# RESOLVER_RESOLVER_REGS_502CB000h register map
Vendor: Texas Instruments
Peripheral module from a debugger description file (folder AM263P).
Registers are 32-bit, read-write, reset 0x0 unless marked. A register's access mark holds for its fields unless they carry their own. Offsets are as the file gives them; lines under a group give offsets from that group; [hi:lo] are bit positions; {n}, {i} and the like mark numbered series; 'fields as' and 'values as' point back to an identical list; <NAME> marks a mode.

## RESOLVER_REGS (part 1 of 2)
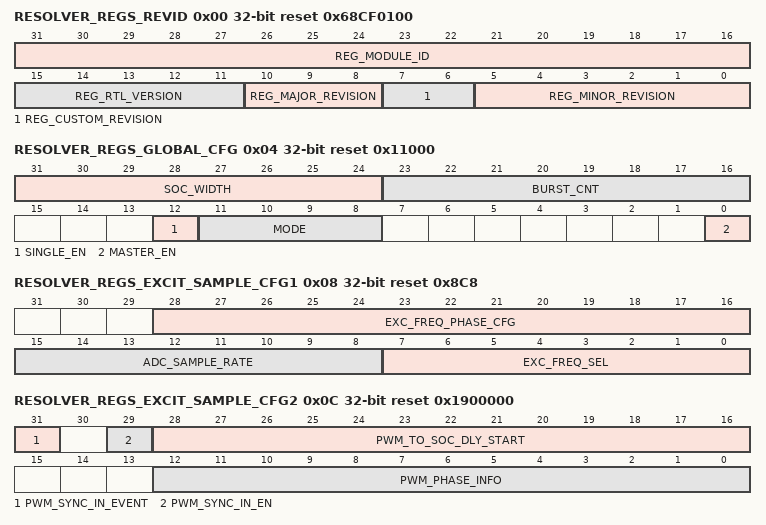
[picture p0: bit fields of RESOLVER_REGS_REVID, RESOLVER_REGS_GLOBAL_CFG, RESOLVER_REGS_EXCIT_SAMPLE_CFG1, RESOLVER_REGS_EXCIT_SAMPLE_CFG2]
0x00 RESOLVER_REGS_REVID ro reset 0x68CF0100 — The Module and Version Register identifies the module identifier and revision of the RTL module.
  [31:16] REG_MODULE_ID — Resolver module ID
  [15:11] REG_RTL_VERSION — RTL Version.
  [10:8] REG_MAJOR_REVISION — Major Revision.
  [7:6] REG_CUSTOM_REVISION — Custom Revision.
  [5:0] REG_MINOR_REVISION — Minor Revision.
0x04 RESOLVER_REGS_GLOBAL_CFG reset 0x11000 — Global Configuration.
  [31:24] SOC_WIDTH — Extension of Start Of Conversion(SOC) pulse width. Width = 40ns + 20ns*soc_width
  [23:16] BURST_CNT — This defines the number of burst per sample, 1 is no burst, 2 is 2 samples which will get avg ect.., only valid values are 1,2,4,8,16, and 32
  [12] SINGLE_EN — 1 single adc mode 0 diff adc mode
  [11:8] MODE — This defines the mode of the resolver , the user has 6 options to configure
  [0] MASTER_EN — Master Enable must leave disabled when cfg is updated0:Disabled1:Enabled When 0 it reset all counters, SM, SEQ, ect..
0x08 RESOLVER_REGS_EXCIT_SAMPLE_CFG1 reset 0x8C8 — Excitation and Sample Configuration1.
  [28:16] EXC_FREQ_PHASE_CFG — Defines when to start the8000counter to the SIN LUT, this is one time per master_en 0 -> 1
  [15:8] ADC_SAMPLE_RATE — ADC Over Sample Rate (<value> * 2) 0 = Reserved 1 = OSR2 .. 16 = OSR32 > 16 = Reserved
  [7:0] EXC_FREQ_SEL — Exciter Frequency select (<freq *10> * 10), only 200-20k, 100-10k, and 50-5k is valid
0x0C RESOLVER_REGS_EXCIT_SAMPLE_CFG2 access not given reset 0x1900000 — Excitation and Sample Configuration2.
  [31] PWM_SYNC_IN_EVENT — This tells SW we had a pwm_sync_in event after master_en is set, w1tc but new start you must de-assert mater_en to re-arm (access R/W1TC)
  [29] PWM_SYNC_IN_EN rw — 0 disable 1 enable the pwm_sync_in dep to start soc is
  [28:16] PWM_TO_SOC_DLY_START rw — This delay start of SEQ SOC in steps of 800KHz, this is a one time event per master_en 0 -> 1, first power up needs to be 500uS , so reset state of 400 will hit this
  [12:0] PWM_PHASE_INFO ro — This is the latched value of the last pwm_sync_in risge event
0x10 RESOLVER_REGS_EXCIT_SAMPLE_CFG3 reset 0xEF — Excitation and Sample Configuration2.
  [7:0] EXC_AMP_CTRL — Defines the amplitude scale, 249 is 100%, > 250 is res
0x14 RESOLVER_REGS_IRQSTATUS_RAW_SYS access not given — Interrupt Raw Status Register For Resolver.
  [0] SEQ_ERR — Raw status of error interrupt for seq_cmp_err Write 1 to set the (raw) status, mostly for debug. Writing a 0 has no effect. (access R/W1TS)
0x18 RESOLVER_REGS_IRQSTATUS_SYS access not given — Interrupt Status Register For Resolver.
  [0] SEQ_ERR — Enabled status of error interrupt for seq_cmp_err Write 1 to clear the status after interrupt has been serviced (raw status gets cleared, i.e. even if not enabled). Writing a 0 has no effect. (access R/W1TC)
0x1C RESOLVER_REGS_IRQENABLE_SET_SYS access not given — Interrupt Enable Set Register For Resolver.
  [0] SEQ_ERR — Enable set for seq_cmp_err . Writing a 1 will enable the interrupt, and set this bit as well as the corresponding Interrupt Enable Clear Register. Writing a 0 has no effect. (access R/W1TS)
0x20 RESOLVER_REGS_IRQENABLE_CLR_SYS access not given — Interrupt Enable Clear Register For Resolver.
  [0] SEQ_ERR — Enable clr for seq_cmp_err. Writing a 1 will disable the interrupt, and set this bit as well as the corresponding Interrupt Enable set Register. Writing a 0 has no effect. (access R/W1TS)
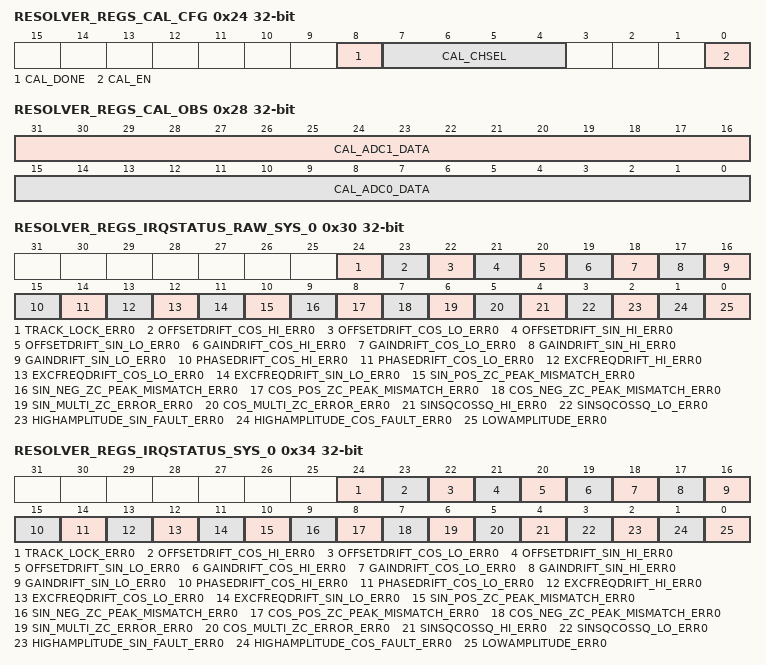
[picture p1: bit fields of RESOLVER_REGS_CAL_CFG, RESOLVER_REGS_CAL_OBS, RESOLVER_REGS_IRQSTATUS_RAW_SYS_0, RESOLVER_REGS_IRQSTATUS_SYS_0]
0x24 RESOLVER_REGS_CAL_CFG access not given — CAL Config.
  [8] CAL_DONE — This tells SW CAL data is updated, it will not do a new CAL sample until this is cleared (access R/W1TC)
  [7:4] CAL_CHSEL rw — This defines the ADC channel for ADC0 and ADC1 For 263P bit 4 is reserved To determine correct value per SOC refer to the ADC Spec for that SOC
  [0] CAL_EN rw — Enable CAL, each wrt of one will start cal, can not start new one until the other is done and done is cleared , to start a new cal just wrt a new one to this mmr
0x28 RESOLVER_REGS_CAL_OBS ro — CAL ADC0 and ADC1 Data.
  [31:16] CAL_ADC1_DATA — Signed ADC1 Data from CAL channel sample if mode enables ie not mode 1 and mode 2
  [15:0] CAL_ADC0_DATA — Signed ADC0 Data from CAL channel sample
0x30 RESOLVER_REGS_IRQSTATUS_RAW_SYS_0 access not given — Interrupt Raw Status Register for Core0.
  [24] TRACK_LOCK_ERR0 — Raw status of error interrupt for track_lock_err Write 1 to set the (raw) status, mostly for debug. Writing a 0 has no effect. (access R/W1TS)
  [23] OFFSETDRIFT_COS_HI_ERR0 — Raw status of error interrupt for offsetdrift_cos_hi_err Write 1 to set the (raw) status, mostly for debug. Writing a 0 has no effect. (access R/W1TS)
  [22] OFFSETDRIFT_COS_LO_ERR0 — Raw status of error interrupt for offsetdrift_cos_lo_err Write 1 to set the (raw) status, mostly for debug. Writing a 0 has no effect. (access R/W1TS)
  [21] OFFSETDRIFT_SIN_HI_ERR0 — Raw status of error interrupt for offsetdrift_sin_hi_err Write 1 to set the (raw) status, mostly for debug. Writing a 0 has no effect. (access R/W1TS)
  [20] OFFSETDRIFT_SIN_LO_ERR0 — Raw status of error interrupt for offsetdrift_sin_lo_err Write 1 to set the (raw) status, mostly for debug. Writing a 0 has no effect. (access R/W1TS)
  [19] GAINDRIFT_COS_HI_ERR0 — Raw status of error interrupt for gaindrift_cos_hi_err Write 1 to set the (raw) status, mostly for debug. Writing a 0 has no effect. (access R/W1TS)
  [18] GAINDRIFT_COS_LO_ERR0 — Raw status of error interrupt for gaindrift_cos_lo_err Write 1 to set the (raw) status, mostly for debug. Writing a 0 has no effect. (access R/W1TS)
  [17] GAINDRIFT_SIN_HI_ERR0 — Raw status of error interrupt for gaindrift_sin_hi_err Write 1 to set the (raw) status, mostly for debug. Writing a 0 has no effect. (access R/W1TS)
  [16] GAINDRIFT_SIN_LO_ERR0 — Raw status of error interrupt for gaindrift_sin_lo_err Write 1 to set the (raw) status, mostly for debug. Writing a 0 has no effect. (access R/W1TS)
  [15] PHASEDRIFT_COS_HI_ERR0 — Raw status of error interrupt for phasedrift_cos_hi_err Write 1 to set the (raw) status, mostly for debug. Writing a 0 has no effect. (access R/W1TS)
  [14] PHASEDRIFT_COS_LO_ERR0 — Raw status of error interrupt for phasedrift_cos_lo_err Write 1 to set the (raw) status, mostly for debug. Writing a 0 has no effect. (access R/W1TS)
  [13] EXCFREQDRIFT_HI_ERR0 — Raw status of error interrupt for excfreqdrift_hi_err Write 1 to set the (raw) status, mostly for debug. Writing a 0 has no effect. (access R/W1TS)
  [12] EXCFREQDRIFT_COS_LO_ERR0 — Raw status of error interrupt for excfreqdrift_cos_lo_err Write 1 to set the (raw) status, mostly for debug. Writing a 0 has no effect. (access R/W1TS)
  [11] EXCFREQDRIFT_SIN_LO_ERR0 — Raw status of error interrupt for excfreqdrift_sin_lo_err Write 1 to set the (raw) status, mostly for debug. Writing a 0 has no effect. (access R/W1TS)
  [10] SIN_POS_ZC_PEAK_MISMATCH_ERR0 — Raw status of error interrupt for sin_pos_zc_peak_mismatch_err Write 1 to set the (raw) status, mostly for debug. Writing a 0 has no effect. (access R/W1TS)
  [9] SIN_NEG_ZC_PEAK_MISMATCH_ERR0 — Raw status of error interrupt for sin_neg_zc_peak_mismatch_err Write 1 to set the (raw) status, mostly for debug. Writing a 0 has no effect. (access R/W1TS)
  [8] COS_POS_ZC_PEAK_MISMATCH_ERR0 — Raw status of error interrupt for cos_pos_zc_peak_mismatch_err Write 1 to set the (raw) status, mostly for debug. Writing a 0 has no effect. (access R/W1TS)
  [7] COS_NEG_ZC_PEAK_MISMATCH_ERR0 — Raw status of error interrupt for cos_neg_zc_peak_mismatch_err Write 1 to set the (raw) status, mostly for debug. Writing a 0 has no effect. (access R/W1TS)
  [6] SIN_MULTI_ZC_ERROR_ERR0 — Raw status of error interrupt for sin_multi_zc_error_err Write 1 to set the (raw) status, mostly for debug. Writing a 0 has no effect. (access R/W1TS)
  [5] COS_MULTI_ZC_ERROR_ERR0 — Raw status of error interrupt for cos_multi_zc_error_err Write 1 to set the (raw) status, mostly for debug. Writing a 0 has no effect. (access R/W1TS)
  [4] SINSQCOSSQ_HI_ERR0 — Raw status of error interrupt for sinsqcossq_hi_err Write 1 to set the (raw) status, mostly for debug. Writing a 0 has no effect. (access R/W1TS)
  [3] SINSQCOSSQ_LO_ERR0 — Raw status of error interrupt for sinsqcossq_lo_err Write 1 to set the (raw) status, mostly for debug. Writing a 0 has no effect. (access R/W1TS)
  [2] HIGHAMPLITUDE_SIN_FAULT_ERR0 — Raw status of error interrupt for highamplitude_sin_fault_err Write 1 to set the (raw) status, mostly for debug. Writing a 0 has no effect. (access R/W1TS)
  [1] HIGHAMPLITUDE_COS_FAULT_ERR0 — Raw status of error interrupt for highamplitude_cos_fault_err Write 1 to set the (raw) status, mostly for debug. Writing a 0 has no effect. (access R/W1TS)
  [0] LOWAMPLITUDE_ERR0 — Raw status of error interrupt for lowamplitude_err Write 1 to set the (raw) status, mostly for debug. Writing a 0 has no effect. (access R/W1TS)
0x34 RESOLVER_REGS_IRQSTATUS_SYS_0 access not given — Interrupt Status Register for Core0.
  [24] TRACK_LOCK_ERR0 — Enabled status of error interrupt for track_lock_err Write 1 to clear the status after interrupt has been serviced (raw status gets cleared, i.e. even if not enabled). Writing a 0 has no effect. (access R/W1TC)
  [23] OFFSETDRIFT_COS_HI_ERR0 — Enabled status of error interrupt for offsetdrift_cos_hi_err Write 1 to clear the status after interrupt has been serviced (raw status gets cleared, i.e. even if not enabled). Writing a 0 has no effect. (access R/W1TC)
  [22] OFFSETDRIFT_COS_LO_ERR0 — Enabled status of error interrupt for offsetdrift_cos_lo_err Write 1 to clear the status after interrupt has been serviced (raw status gets cleared, i.e. even if not enabled). Writing a 0 has no effect. (access R/W1TC)
  [21] OFFSETDRIFT_SIN_HI_ERR0 — Enabled status of error interrupt for offsetdrift_sin_hi_err Write 1 to clear the status after interrupt has been serviced (raw status gets cleared, i.e. even if not enabled). Writing a 0 has no effect. (access R/W1TC)
  [20] OFFSETDRIFT_SIN_LO_ERR0 — Enabled status of error interrupt for offsetdrift_sin_lo_err Write 1 to clear the status after interrupt has been serviced (raw status gets cleared, i.e. even if not enabled). Writing a 0 has no effect. (access R/W1TC)
  [19] GAINDRIFT_COS_HI_ERR0 — Enabled status of error interrupt for gaindrift_cos_hi_err Write 1 to clear the status after interrupt has been serviced (raw status gets cleared, i.e. even if not enabled). Writing a 0 has no effect. (access R/W1TC)
  [18] GAINDRIFT_COS_LO_ERR0 — Enabled status of error interrupt for gaindrift_cos_lo_err Write 1 to clear the status after interrupt has been serviced (raw status gets cleared, i.e. even if not enabled). Writing a 0 has no effect. (access R/W1TC)
  [17] GAINDRIFT_SIN_HI_ERR0 — Enabled status of error interrupt for gaindrift_sin_hi_err Write 1 to clear the status after interrupt has been serviced (raw status gets cleared, i.e. even if not enabled). Writing a 0 has no effect. (access R/W1TC)
  [16] GAINDRIFT_SIN_LO_ERR0 — Enabled status of error interrupt for gaindrift_sin_lo_err Write 1 to clear the status after interrupt has been serviced (raw status gets cleared, i.e. even if not enabled). Writing a 0 has no effect. (access R/W1TC)
  [15] PHASEDRIFT_COS_HI_ERR0 — Enabled status of error interrupt for phasedrift_cos_hi_err Write 1 to clear the status after interrupt has been serviced (raw status gets cleared, i.e. even if not enabled). Writing a 0 has no effect. (access R/W1TC)
  [14] PHASEDRIFT_COS_LO_ERR0 — Enabled status of error interrupt for phasedrift_cos_lo_err Write 1 to clear the status after interrupt has been serviced (raw status gets cleared, i.e. even if not enabled). Writing a 0 has no effect. (access R/W1TC)
  [13] EXCFREQDRIFT_HI_ERR0 — Enabled status of error interrupt for excfreqdrift_hi_err Write 1 to clear the status after interrupt has been serviced (raw status gets cleared, i.e. even if not enabled). Writing a 0 has no effect. (access R/W1TC)
  [12] EXCFREQDRIFT_COS_LO_ERR0 — Enabled status of error interrupt for excfreqdrift_cos_lo_err Write 1 to clear the status after interrupt has been serviced (raw status gets cleared, i.e. even if not enabled). Writing a 0 has no effect. (access R/W1TC)
  [11] EXCFREQDRIFT_SIN_LO_ERR0 — Enabled status of error interrupt for excfreqdrift_sin_lo_err Write 1 to clear the status after interrupt has been serviced (raw status gets cleared, i.e. even if not enabled). Writing a 0 has no effect. (access R/W1TC)
  [10] SIN_POS_ZC_PEAK_MISMATCH_ERR0 — Enabled status of error interrupt for sin_pos_zc_peak_mismatch_err Write 1 to clear the status after interrupt has been serviced (raw status gets cleared, i.e. even if not enabled). Writing a 0 has no effect. (access R/W1TC)
  [9] SIN_NEG_ZC_PEAK_MISMATCH_ERR0 — Enabled status of error interrupt for sin_neg_zc_peak_mismatch_err Write 1 to clear the status after interrupt has been serviced (raw status gets cleared, i.e. even if not enabled). Writing a 0 has no effect. (access R/W1TC)
  [8] COS_POS_ZC_PEAK_MISMATCH_ERR0 — Enabled status of error interrupt for cos_pos_zc_peak_mismatch_err Write 1 to clear the status after interrupt has been serviced (raw status gets cleared, i.e. even if not enabled). Writing a 0 has no effect. (access R/W1TC)
  [7] COS_NEG_ZC_PEAK_MISMATCH_ERR0 — Enabled status of error interrupt for cos_neg_zc_peak_mismatch_err Write 1 to clear the status after interrupt has been serviced (raw status gets cleared, i.e. even if not enabled). Writing a 0 has no effect. (access R/W1TC)
  [6] SIN_MULTI_ZC_ERROR_ERR0 — Enabled status of error interrupt for sin_multi_zc_error_err Write 1 to clear the status after interrupt has been serviced (raw status gets cleared, i.e. even if not enabled). Writing a 0 has no effect. (access R/W1TC)
  [5] COS_MULTI_ZC_ERROR_ERR0 — Enabled status of error interrupt for cos_multi_zc_error_err Write 1 to clear the status after interrupt has been serviced (raw status gets cleared, i.e. even if not enabled). Writing a 0 has no effect. (access R/W1TC)
  [4] SINSQCOSSQ_HI_ERR0 — Enabled status of error interrupt for sinsqcossq_hi_err Write 1 to clear the status after interrupt has been serviced (raw status gets cleared, i.e. even if not enabled). Writing a 0 has no effect. (access R/W1TC)
  [3] SINSQCOSSQ_LO_ERR0 — Enabled status of error interrupt for sinsqcossq_lo_err Write 1 to clear the status after interrupt has been serviced (raw status gets cleared, i.e. even if not enabled). Writing a 0 has no effect. (access R/W1TC)
  [2] HIGHAMPLITUDE_SIN_FAULT_ERR0 — Enabled status of error interrupt for highamplitude_sin_fault_err Write 1 to clear the status after interrupt has been serviced (raw status gets cleared, i.e. even if not enabled). Writing a 0 has no effect. (access R/W1TC)
  [1] HIGHAMPLITUDE_COS_FAULT_ERR0 — Enabled status of error interrupt for highamplitude_cos_fault_err Write 1 to clear the status after interrupt has been serviced (raw status gets cleared, i.e. even if not enabled). Writing a 0 has no effect. (access R/W1TC)
  [0] LOWAMPLITUDE_ERR0 — Enabled status of error interrupt for lowamplitude_err Write 1 to clear the status after interrupt has been serviced (raw status gets cleared, i.e. even if not enabled). Writing a 0 has no effect. (access R/W1TC)
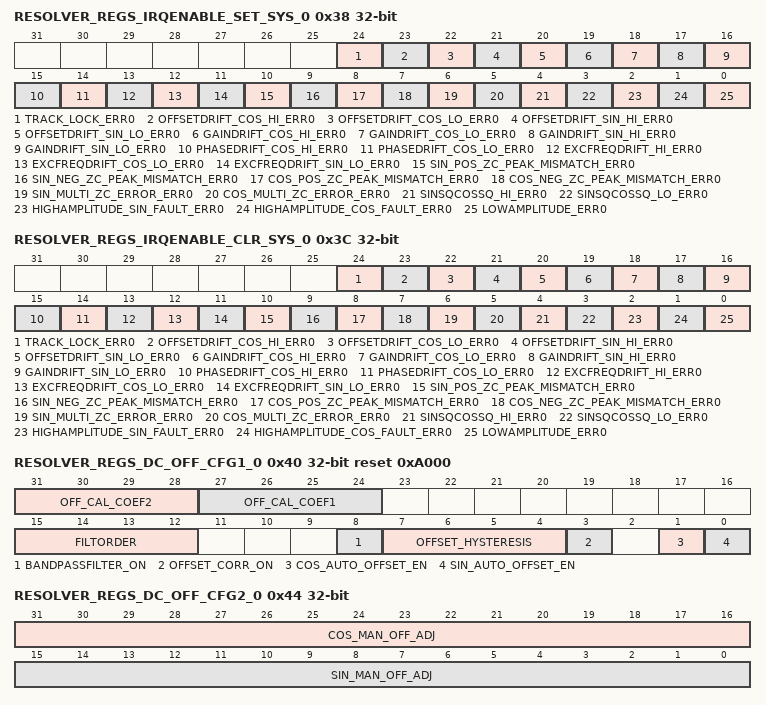
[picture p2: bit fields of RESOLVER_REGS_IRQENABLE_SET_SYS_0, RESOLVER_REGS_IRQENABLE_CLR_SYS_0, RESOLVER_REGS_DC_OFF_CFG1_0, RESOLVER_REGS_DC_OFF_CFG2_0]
0x38 RESOLVER_REGS_IRQENABLE_SET_SYS_0 access not given — Interrupt Enable Set Register for Core0.
  [24] TRACK_LOCK_ERR0 — Enable set for track_lock_err . Writing a 1 will enable the interrupt, and set this bit as well as the corresponding Interrupt Enable Clear Register. Writing a 0 has no effect. (access R/W1TS)
  [23] OFFSETDRIFT_COS_HI_ERR0 — Enable set for offsetdrift_cos_hi_err . Writing a 1 will enable the interrupt, and set this bit as well as the corresponding Interrupt Enable Clear Register. Writing a 0 has no effect. (access R/W1TS)
  [22] OFFSETDRIFT_COS_LO_ERR0 — Enable set for offsetdrift_cos_lo_err . Writing a 1 will enable the interrupt, and set this bit as well as the corresponding Interrupt Enable Clear Register. Writing a 0 has no effect. (access R/W1TS)
  [21] OFFSETDRIFT_SIN_HI_ERR0 — Enable set for offsetdrift_sin_hi_err . Writing a 1 will enable the interrupt, and set this bit as well as the corresponding Interrupt Enable Clear Register. Writing a 0 has no effect. (access R/W1TS)
  [20] OFFSETDRIFT_SIN_LO_ERR0 — Enable set for offsetdrift_sin_lo_err . Writing a 1 will enable the interrupt, and set this bit as well as the corresponding Interrupt Enable Clear Register. Writing a 0 has no effect. (access R/W1TS)
  [19] GAINDRIFT_COS_HI_ERR0 — Enable set for gaindrift_cos_hi_err . Writing a 1 will enable the interrupt, and set this bit as well as the corresponding Interrupt Enable Clear Register. Writing a 0 has no effect. (access R/W1TS)
  [18] GAINDRIFT_COS_LO_ERR0 — Enable set for gaindrift_cos_lo_err . Writing a 1 will enable the interrupt, and set this bit as well as the corresponding Interrupt Enable Clear Register. Writing a 0 has no effect. (access R/W1TS)
  [17] GAINDRIFT_SIN_HI_ERR0 — Enable set for gaindrift_sin_hi_err . Writing a 1 will enable the interrupt, and set this bit as well as the corresponding Interrupt Enable Clear Register. Writing a 0 has no effect. (access R/W1TS)
  [16] GAINDRIFT_SIN_LO_ERR0 — Enable set for gaindrift_sin_lo_err . Writing a 1 will enable the interrupt, and set this bit as well as the corresponding Interrupt Enable Clear Register. Writing a 0 has no effect. (access R/W1TS)
  [15] PHASEDRIFT_COS_HI_ERR0 — Enable set for phasedrift_cos_hi_err . Writing a 1 will enable the interrupt, and set this bit as well as the corresponding Interrupt Enable Clear Register. Writing a 0 has no effect. (access R/W1TS)
  [14] PHASEDRIFT_COS_LO_ERR0 — Enable set for phasedrift_cos_lo_err . Writing a 1 will enable the interrupt, and set this bit as well as the corresponding Interrupt Enable Clear Register. Writing a 0 has no effect. (access R/W1TS)
  [13] EXCFREQDRIFT_HI_ERR0 — Enable set for excfreqdrift_hi_err . Writing a 1 will enable the interrupt, and set this bit as well as the corresponding Interrupt Enable Clear Register. Writing a 0 has no effect. (access R/W1TS)
  [12] EXCFREQDRIFT_COS_LO_ERR0 — Enable set for excfreqdrift_cos_lo_err . Writing a 1 will enable the interrupt, and set this bit as well as the corresponding Interrupt Enable Clear Register. Writing a 0 has no effect. (access R/W1TS)
  [11] EXCFREQDRIFT_SIN_LO_ERR0 — Enable set for excfreqdrift_sin_lo_err . Writing a 1 will enable the interrupt, and set this bit as well as the corresponding Interrupt Enable Clear Register. Writing a 0 has no effect. (access R/W1TS)
  [10] SIN_POS_ZC_PEAK_MISMATCH_ERR0 — Enable set for sin_pos_zc_peak_mismatch_err . Writing a 1 will enable the interrupt, and set this bit as well as the corresponding Interrupt Enable Clear Register. Writing a 0 has no effect. (access R/W1TS)
  [9] SIN_NEG_ZC_PEAK_MISMATCH_ERR0 — Enable set for sin_neg_zc_peak_mismatch_err . Writing a 1 will enable the interrupt, and set this bit as well as the corresponding Interrupt Enable Clear Register. Writing a 0 has no effect. (access R/W1TS)
  [8] COS_POS_ZC_PEAK_MISMATCH_ERR0 — Enable set for cos_pos_zc_peak_mismatch_err . Writing a 1 will enable the interrupt, and set this bit as well as the corresponding Interrupt Enable Clear Register. Writing a 0 has no effect. (access R/W1TS)
  [7] COS_NEG_ZC_PEAK_MISMATCH_ERR0 — Enable set for cos_neg_zc_peak_mismatch_err . Writing a 1 will enable the interrupt, and set this bit as well as the corresponding Interrupt Enable Clear Register. Writing a 0 has no effect. (access R/W1TS)
  [6] SIN_MULTI_ZC_ERROR_ERR0 — Enable set for sin_multi_zc_error_err . Writing a 1 will enable the interrupt, and set this bit as well as the corresponding Interrupt Enable Clear Register. Writing a 0 has no effect. (access R/W1TS)
  [5] COS_MULTI_ZC_ERROR_ERR0 — Enable set for cos_multi_zc_error_err . Writing a 1 will enable the interrupt, and set this bit as well as the corresponding Interrupt Enable Clear Register. Writing a 0 has no effect. (access R/W1TS)
  [4] SINSQCOSSQ_HI_ERR0 — Enable set for sinsqcossq_hi_err . Writing a 1 will enable the interrupt, and set this bit as well as the corresponding Interrupt Enable Clear Register. Writing a 0 has no effect. (access R/W1TS)
  [3] SINSQCOSSQ_LO_ERR0 — Enable set for sinsqcossq_lo_err . Writing a 1 will enable the interrupt, and set this bit as well as the corresponding Interrupt Enable Clear Register. Writing a 0 has no effect. (access R/W1TS)
  [2] HIGHAMPLITUDE_SIN_FAULT_ERR0 — Enable set for highamplitude_sin_fault_err . Writing a 1 will enable the interrupt, and set this bit as well as the corresponding Interrupt Enable Clear Register. Writing a 0 has no effect. (access R/W1TS)
  [1] HIGHAMPLITUDE_COS_FAULT_ERR0 — Enable set for highamplitude_cos_fault_err . Writing a 1 will enable the interrupt, and set this bit as well as the corresponding Interrupt Enable Clear Register. Writing a 0 has no effect. (access R/W1TS)
  [0] LOWAMPLITUDE_ERR0 — Enable set for lowamplitude_err . Writing a 1 will enable the interrupt, and set this bit as well as the corresponding Interrupt Enable Clear Register. Writing a 0 has no effect. (access R/W1TS)
0x3C RESOLVER_REGS_IRQENABLE_CLR_SYS_0 access not given — Interrupt Enable Clear Register for Core0.
  [24] TRACK_LOCK_ERR0 — Enable clr for track_lock_err. Writing a 1 will disable the interrupt, and set this bit as well as the corresponding Interrupt Enable set Register. Writing a 0 has no effect. (access R/W1TS)
  [23] OFFSETDRIFT_COS_HI_ERR0 — Enable clr for offsetdrift_cos_hi_err. Writing a 1 will disable the interrupt, and set this bit as well as the corresponding Interrupt Enable set Register. Writing a 0 has no effect. (access R/W1TS)
  [22] OFFSETDRIFT_COS_LO_ERR0 — Enable clr for offsetdrift_cos_lo_err. Writing a 1 will disable the interrupt, and set this bit as well as the corresponding Interrupt Enable set Register. Writing a 0 has no effect. (access R/W1TS)
  [21] OFFSETDRIFT_SIN_HI_ERR0 — Enable clr for offsetdrift_sin_hi_err. Writing a 1 will disable the interrupt, and set this bit as well as the corresponding Interrupt Enable set Register. Writing a 0 has no effect. (access R/W1TS)
  [20] OFFSETDRIFT_SIN_LO_ERR0 — Enable clr for offsetdrift_sin_lo_err. Writing a 1 will disable the interrupt, and set this bit as well as the corresponding Interrupt Enable set Register. Writing a 0 has no effect. (access R/W1TS)
  [19] GAINDRIFT_COS_HI_ERR0 — Enable clr for gaindrift_cos_hi_err. Writing a 1 will disable the interrupt, and set this bit as well as the corresponding Interrupt Enable set Register. Writing a 0 has no effect. (access R/W1TS)
  [18] GAINDRIFT_COS_LO_ERR0 — Enable clr for gaindrift_cos_lo_err. Writing a 1 will disable the interrupt, and set this bit as well as the corresponding Interrupt Enable set Register. Writing a 0 has no effect. (access R/W1TS)
  [17] GAINDRIFT_SIN_HI_ERR0 — Enable clr for gaindrift_sin_hi_err. Writing a 1 will disable the interrupt, and set this bit as well as the corresponding Interrupt Enable set Register. Writing a 0 has no effect. (access R/W1TS)
  [16] GAINDRIFT_SIN_LO_ERR0 — Enable clr for gaindrift_sin_lo_err. Writing a 1 will disable the interrupt, and set this bit as well as the corresponding Interrupt Enable set Register. Writing a 0 has no effect. (access R/W1TS)
  [15] PHASEDRIFT_COS_HI_ERR0 — Enable clr for phasedrift_cos_hi_err. Writing a 1 will disable the interrupt, and set this bit as well as the corresponding Interrupt Enable set Register. Writing a 0 has no effect. (access R/W1TS)
  [14] PHASEDRIFT_COS_LO_ERR0 — Enable clr for phasedrift_cos_lo_err. Writing a 1 will disable the interrupt, and set this bit as well as the corresponding Interrupt Enable set Register. Writing a 0 has no effect. (access R/W1TS)
  [13] EXCFREQDRIFT_HI_ERR0 — Enable clr for excfreqdrift_hi_err. Writing a 1 will disable the interrupt, and set this bit as well as the corresponding Interrupt Enable set Register. Writing a 0 has no effect. (access R/W1TS)
  [12] EXCFREQDRIFT_COS_LO_ERR0 — Enable clr for excfreqdrift_cos_lo_err. Writing a 1 will disable the interrupt, and set this bit as well as the corresponding Interrupt Enable set Register. Writing a 0 has no effect. (access R/W1TS)
  [11] EXCFREQDRIFT_SIN_LO_ERR0 — Enable clr for excfreqdrift_sin_lo_err. Writing a 1 will disable the interrupt, and set this bit as well as the corresponding Interrupt Enable set Register. Writing a 0 has no effect. (access R/W1TS)
  [10] SIN_POS_ZC_PEAK_MISMATCH_ERR0 — Enable clr for sin_pos_zc_peak_mismatch_err. Writing a 1 will disable the interrupt, and set this bit as well as the corresponding Interrupt Enable set Register. Writing a 0 has no effect. (access R/W1TS)
  [9] SIN_NEG_ZC_PEAK_MISMATCH_ERR0 — Enable clr for sin_neg_zc_peak_mismatch_err. Writing a 1 will disable the interrupt, and set this bit as well as the corresponding Interrupt Enable set Register. Writing a 0 has no effect. (access R/W1TS)
  [8] COS_POS_ZC_PEAK_MISMATCH_ERR0 — Enable clr for cos_pos_zc_peak_mismatch_err. Writing a 1 will disable the interrupt, and set this bit as well as the corresponding Interrupt Enable set Register. Writing a 0 has no effect. (access R/W1TS)
  [7] COS_NEG_ZC_PEAK_MISMATCH_ERR0 — Enable clr for cos_neg_zc_peak_mismatch_err. Writing a 1 will disable the interrupt, and set this bit as well as the corresponding Interrupt Enable set Register. Writing a 0 has no effect. (access R/W1TS)
  [6] SIN_MULTI_ZC_ERROR_ERR0 — Enable clr for sin_multi_zc_error_err. Writing a 1 will disable the interrupt, and set this bit as well as the corresponding Interrupt Enable set Register. Writing a 0 has no effect. (access R/W1TS)
  [5] COS_MULTI_ZC_ERROR_ERR0 — Enable clr for cos_multi_zc_error_err. Writing a 1 will disable the interrupt, and set this bit as well as the corresponding Interrupt Enable set Register. Writing a 0 has no effect. (access R/W1TS)
  [4] SINSQCOSSQ_HI_ERR0 — Enable clr for sinsqcossq_hi_err. Writing a 1 will disable the interrupt, and set this bit as well as the corresponding Interrupt Enable set Register. Writing a 0 has no effect. (access R/W1TS)
  [3] SINSQCOSSQ_LO_ERR0 — Enable clr for sinsqcossq_lo_err. Writing a 1 will disable the interrupt, and set this bit as well as the corresponding Interrupt Enable set Register. Writing a 0 has no effect. (access R/W1TS)
  [2] HIGHAMPLITUDE_SIN_FAULT_ERR0 — Enable clr for highamplitude_sin_fault_err. Writing a 1 will disable the interrupt, and set this bit as well as the corresponding Interrupt Enable set Register. Writing a 0 has no effect. (access R/W1TS)
  [1] HIGHAMPLITUDE_COS_FAULT_ERR0 — Enable clr for highamplitude_cos_fault_err. Writing a 1 will disable the interrupt, and set this bit as well as the corresponding Interrupt Enable set Register. Writing a 0 has no effect. (access R/W1TS)
  [0] LOWAMPLITUDE_ERR0 — Enable clr for lowamplitude_err. Writing a 1 will disable the interrupt, and set this bit as well as the corresponding Interrupt Enable set Register. Writing a 0 has no effect. (access R/W1TS)
0x40 RESOLVER_REGS_DC_OFF_CFG1_0 reset 0xA000 — DC Offset Config1.
  [31:28] OFF_CAL_COEF2 — Offset calibration coefficient2 dc offset
  [27:24] OFF_CAL_COEF1 — Offset calibration coefficient1 dc offset
  [15:12] FILTORDER — NOT USED
  [8] BANDPASSFILTER_ON — To enable the bandpass filter before DC offset logix
  [7:4] OFFSET_HYSTERESIS — unsigned. Absolute hysteresis limit.4b(no decimal points) with the16bLSB, ADC data coming16bto the resolver
  [3] OFFSET_CORR_ON — DC Offset Correction On
  [1] COS_AUTO_OFFSET_EN — NOT_USED
  [0] SIN_AUTO_OFFSET_EN — NOT USED
0x44 RESOLVER_REGS_DC_OFF_CFG2_0 — DC Offset Config2.
  [31:16] COS_MAN_OFF_ADJ — Signed Cos manual dc offset
  [15:0] SIN_MAN_OFF_ADJ — Signed Sin manual dc offset
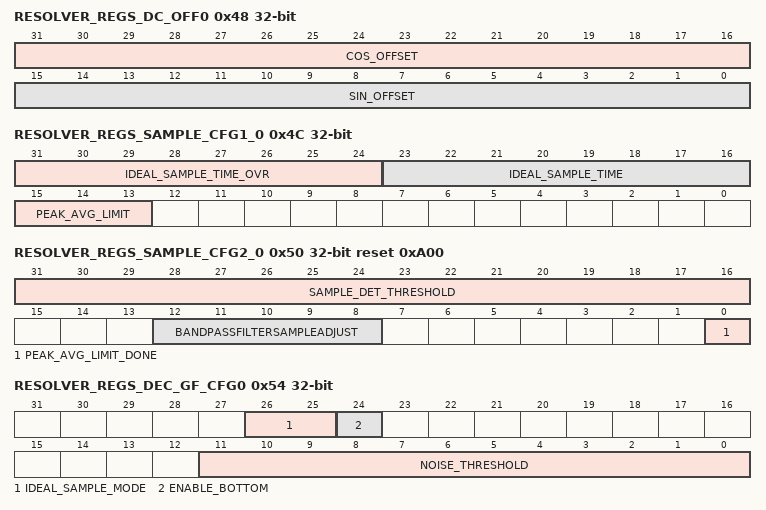
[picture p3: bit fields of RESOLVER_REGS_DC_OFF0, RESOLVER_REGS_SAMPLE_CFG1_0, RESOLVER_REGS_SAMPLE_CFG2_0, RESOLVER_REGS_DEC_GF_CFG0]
0x48 RESOLVER_REGS_DC_OFF0 ro — DC Offset.
  [31:16] COS_OFFSET — Signed Cos auto dc offset
  [15:0] SIN_OFFSET — Signed Sin auto dc offset
0x4C RESOLVER_REGS_SAMPLE_CFG1_0 access per field — Ideal Sample Config1.
  [31:24] IDEAL_SAMPLE_TIME_OVR rw — Ideal sample count Override
  [23:16] IDEAL_SAMPLE_TIME ro — Current Ideal sample count, round down
  [15:13] PEAK_AVG_LIMIT rw — 2^n peakaveragelimit is how many times to average the ideal peak point: 0 to 7
0x50 RESOLVER_REGS_SAMPLE_CFG2_0 access not given reset 0xA00 — Ideal Sample Config2.
  [31:16] SAMPLE_DET_THRESHOLD rw — Abs value, the sig needs to be above to trigger the peak detect
  [12:8] BANDPASSFILTERSAMPLEADJUST rw — Offset compensate the ideal phase time selection if bpass filter enabled note when you are in manual mode, this value is not longer added
  [0] PEAK_AVG_LIMIT_DONE — Ideal sample count training completed, Wrt 1 to Clr (access R/W1TC)
0x54 RESOLVER_REGS_DEC_GF_CFG0 — Dec GF Config.
  [26:25] IDEAL_SAMPLE_MODE — Ideal sample time detection: 0 autodetect, 1 detect on sin channel 2 on cos channel 3 manual
  [24] ENABLE_BOTTOM — This enables bottom wave to get used in the avg
  [11:0] NOISE_THRESHOLD — Abs value, if above use the current moving avg, drop the new data
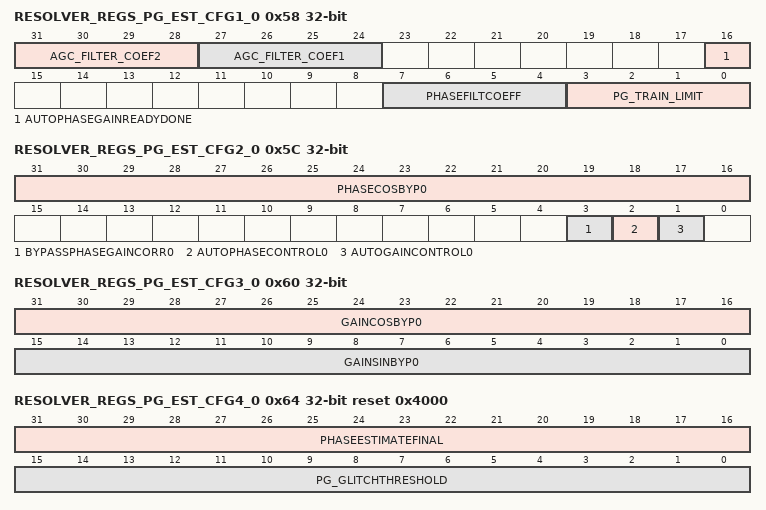
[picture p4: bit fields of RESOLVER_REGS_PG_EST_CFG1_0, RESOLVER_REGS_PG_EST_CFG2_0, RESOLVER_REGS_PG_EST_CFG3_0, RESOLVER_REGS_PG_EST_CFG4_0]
0x58 RESOLVER_REGS_PG_EST_CFG1_0 access not given — Phase and Gain Est for correction block Config1.
  [31:28] AGC_FILTER_COEF2 rw — NOT USED
  [27:24] AGC_FILTER_COEF1 rw — NOT USED
  [16] AUTOPHASEGAINREADYDONE — Status of Auto Gain and Phase Est , set when ready for each cycle , wrt 1 to clear, this has no effect to the correction logic (access R/W1TC)
  [7:4] PHASEFILTCOEFF rw — NOT USED
  [3:0] PG_TRAIN_LIMIT rw — ^n pg_train_limit : 0 to 15
0x5C RESOLVER_REGS_PG_EST_CFG2_0 — Phase and Gain Est for correction block Config2.
  [31:16] PHASECOSBYP0 — Manual Phase Cos correction value
  [3] BYPASSPHASEGAINCORR0 — Enables phase and gain est
  [2] AUTOPHASECONTROL0 — Enable Auto Phase correction
  [1] AUTOGAINCONTROL0 — Enable Auto Gain correction
0x60 RESOLVER_REGS_PG_EST_CFG3_0 — Phase and Gain Est for correction block Config3.
  [31:16] GAINCOSBYP0 — Manual Gain Cos correction value
  [15:0] GAINSINBYP0 — Manual Gain Sin correction value, always pos
0x64 RESOLVER_REGS_PG_EST_CFG4_0 access per field reset 0x4000 — Phase and Gain Est for correction block Config4.
  [31:16] PHASEESTIMATEFINAL ro — Cos Auto Cal Phase correction value cal by est
  [15:0] PG_GLITCHTHRESHOLD rw — glitch threshold to estimate new rotation start in degrees
0x68 RESOLVER_REGS_PG_EST_CFG5_0 ro — Phase and Gain Est for correction block Config5.
  [31:0] COSSQACCFINAL0 — Cos Auto Cal Gain correction value cal by est
0x6C RESOLVER_REGS_PG_EST_CFG6_0 ro — Phase and Gain Est for correction block Config6.
  [31:0] SINSQACCFINAL0 — Sin Auto Cal Gain correction value cal by est
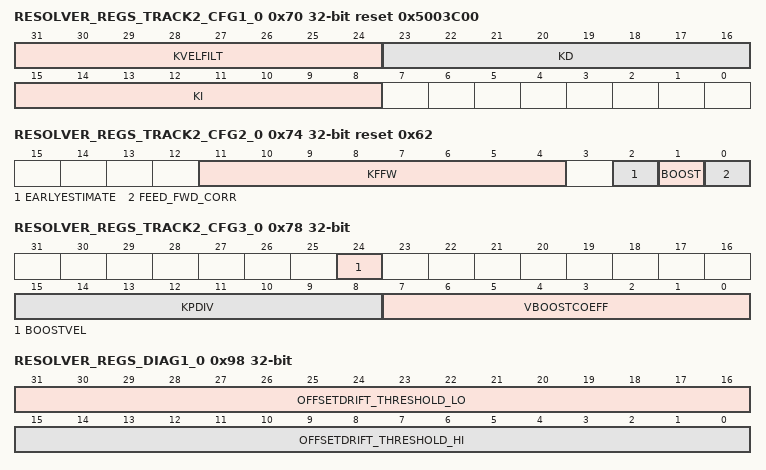
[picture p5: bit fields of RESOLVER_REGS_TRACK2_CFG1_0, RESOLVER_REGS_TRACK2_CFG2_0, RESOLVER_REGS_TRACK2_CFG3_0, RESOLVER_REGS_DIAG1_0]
0x70 RESOLVER_REGS_TRACK2_CFG1_0 reset 0x5003C00 — Track2 Kp, Ki, Kd, Kvelfilt, Kffw, Boost Cfg1 .
  [31:24] KVELFILT
  [23:16] KD — NOT USED
  [15:8] KI
0x74 RESOLVER_REGS_TRACK2_CFG2_0 reset 0x62 — Track2 Feed Fwd Boost Kffw Cfg2.
  [11:4] KFFW
  [2] EARLYESTIMATE — NOT USED
  [1] BOOST — Boost Enable
  [0] FEED_FWD_CORR — NOT USED
0x78 RESOLVER_REGS_TRACK2_CFG3_0 — Track2 Cfg3.
  [24] BOOSTVEL — 0 disables and 1 enables accel/decel compensation for velocity calculation. boost also needs to be 1
  [15:8] KPDIV — Kp proportional path gain
  [7:0] VBOOSTCOEFF — unsigned velocity accel/decel comp coefficient
0x7C RESOLVER_REGS_ANGLE_ARCTAN_0 ro — Angle and Velocity from acrtan .
  [15:0] ANGLE — Signed(2s complement) Angle from arctan -180 to 0 to +180 scaled
0x80 RESOLVER_REGS_ANGLE_TRACK2_0 ro — Angle and Velocity from track2.
  [15:0] ANGLE — Signed(2s complement) Angle from track2 -180 to 0 to +180 scaled
0x84 RESOLVER_REGS_VELOCITY_TRACK2_0 ro — Angle and Velocity from track2.
  [31:0] VELOCITY — This register gives rotation frequency as a function of exc freq and double/single sample mode. Formula on matlab comment. (rotation frequency in Hz, signed based on direction) = (velocity) * (1/Ts) * 1/2^32 Note: if it's top/bottom sampling, Ts = Texc/2, otherwise Ts=Texc
0x88 RESOLVER_REGS_OFFSET_0 access not given reset not defined — SIN and COS Offset.
0x98 RESOLVER_REGS_DIAG1_0 — Diag1 0
  [31:16] OFFSETDRIFT_THRESHOLD_LO — Signed Lo threshold to detect offset drift
  [15:0] OFFSETDRIFT_THRESHOLD_HI — Signed Hi threshold to detect offsetdrift
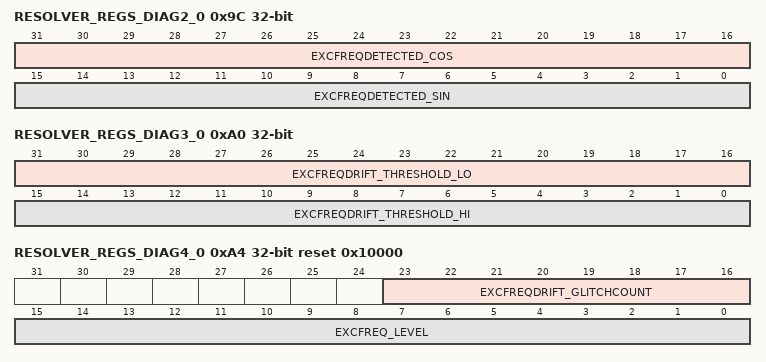
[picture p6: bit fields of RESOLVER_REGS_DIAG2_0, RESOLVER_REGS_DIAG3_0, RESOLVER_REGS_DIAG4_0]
0x9C RESOLVER_REGS_DIAG2_0 ro — Diag2 0
  [31:16] EXCFREQDETECTED_COS — SW OBS Counts detected between zcs for cos excitation frequency
  [15:0] EXCFREQDETECTED_SIN — SW OBS Counts detected between zcs for sin excitation frequency
0xA0 RESOLVER_REGS_DIAG3_0 — Diag3 0
  [31:16] EXCFREQDRIFT_THRESHOLD_LO — Lo threshold to detect excfreqdrift
  [15:0] EXCFREQDRIFT_THRESHOLD_HI — Hi threshold to detect excfreqdrift
0xA4 RESOLVER_REGS_DIAG4_0 reset 0x10000 — Diag4 0
  [23:16] EXCFREQDRIFT_GLITCHCOUNT — Counter limit, how many times before issuing error
  [15:0] EXCFREQ_LEVEL — Threshold on ADC value to detect sin or cos zero crossings
